# NANO103AE_v1 register map
File version: 1.0
Registers are 32-bit, read-write, reset 0x0 unless marked. A register's access mark holds for its fields unless they carry their own. Offsets are from the block's base; [hi:lo] are bit positions.

## WWDT — WWDT Register Map
Base 0x40004100
0x00 WWDT_RLDCNT wo — Window Watchdog Timer Reload Counter Register
  [31:0] RLDCNT — Window Watchdog Timer Reload Counter Register. Writing 0x00005AA5 to this register will reload the Window Watchdog Timer counter value to 0x3F. Note:This registercan only be written when WWDT counter value between 0 and WINCMP, otherwise WWDT will generate RESET signal.
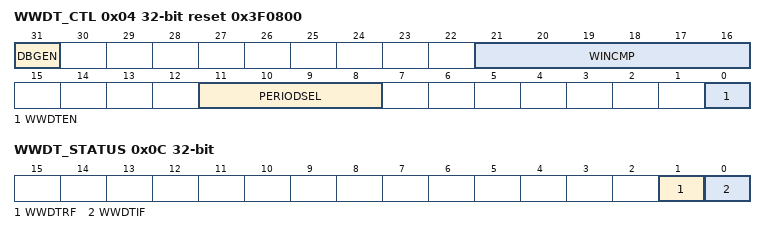
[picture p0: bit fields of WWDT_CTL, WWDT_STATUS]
0x04 WWDT_CTL reset 0x3F0800 — Window Watchdog Timer Control Register
  [31] DBGEN — WWDT Debug EnableBit
    0=WWDT stopped count if system is in Debug mode; 1=WWDT still counted even system is in Debug mode
  [21:16] WINCMP — WWDT Window Compare Bits. Set this register to adjust the valid reload window. Note:WWDT_RLDCNTregistercan only be written when WWDT counter value between 0 and WINCMP, otherwise WWDT will generate RESET signal.
  [11:8] PERIODSEL — WWDT Pre-scale Period Select. These three bits select the pre-scale for the WWDT counter period. Please refer toTable 6.121WWDT Prescaler Value Selection.
  [0] WWDTEN — Window Watchdog EnableBit. Set this bit to enable Window Watchdog timer.
    0=Window Watchdog timer function Disabled; 1=Window Watchdog timer function Enabled
0x08 WWDT_INTEN — Window Watchdog Timer Interrupt Enable Register
  [0] WWDTIEN — WWDT Interrupt Enable Bit. Setting this bit will enable the Window Watchdog timer interrupt function.
    0=Watchdog timer interrupt function Disabled; 1=Watchdog timer interrupt function Enabled
0x0C WWDT_STATUS — Window Watchdog Timer Status Register
  [1] WWDTRF — WWDT Reset Flag. When the WWDT counter down counts to 0 or writes WWDT_RLDCNT during WWDT counter larger than WINCMP, chip will be reset and this bit is set to 1. This bit can be cleared by writing '1' to it.
  [0] WWDTIF — WWDT Compare Match Interrupt Flag. When WWCMP matches the WWDT counter, this bit is set to 1. This bit can be cleared by writing '1' to it.
0x10 WWDT_CNT ro reset 0x3F — Window Watchdog Timer Counter Value Register
  [5:0] CNTDAT — WWDT Counter Value. This register reflects the current counter value of window watchdog.

## ACMP0 — ACMP0 Register Map
Base 0x401D0000
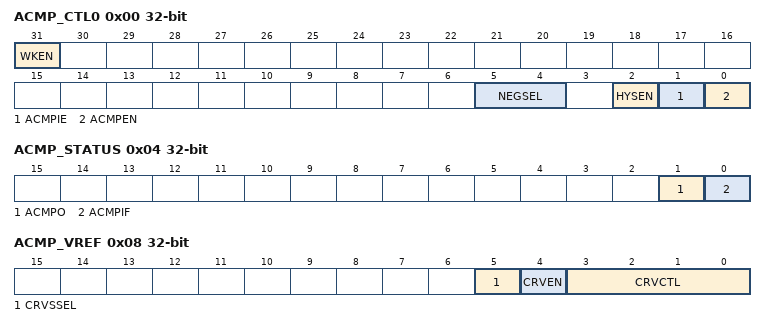
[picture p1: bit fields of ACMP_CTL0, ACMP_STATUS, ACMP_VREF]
0x00 ACMP_CTL0 — Analog Comparator 0 Control Register
  [31] WKEN — Power-down Wake-up Enable Bit
    0=Wake-up function Disabled; 1=Wake-up function Enabled
  [5:4] NEGSEL — Comparator Negative Input Selection
    0=ACMP0_N pin; 1=Internal comparator reference voltage (CRV); 2=Internal reference voltage (Int_VREF); 3=AVSS pin
  [2] HYSEN — Comparator Hysteresis Enable Bit
    0=Comparator 0 hysteresis Disabled; 1=Comparator 0 hysteresis Enabled
  [1] ACMPIE — Comparator Interrupt Enable Bit
    0=Comparator 0 interrupt Disabled; 1=Comparator 0 interrupt Enabled. If WKEN (ACMP_CTL0[31]) is set to 1, the wake-up interrupt function will be enabled as well
  [0] ACMPEN — Comparator Enable Bit
    0=Comparator 0 Disabled; 1=Comparator 0 Enabled
0x04 ACMP_STATUS — Analog Comparator Status Register
  [1] ACMPO — ComparatorOutput. Synchronized to the PCLK to allow reading by software. Cleared when the comparator 0 is disabled, i.e. ACMPEN (ACMP_CTL0[0]) is cleared to 0. Note: This bit is read only.
  [0] ACMPIF — ComparatorInterrupt Flag. This bit is set by hardware whenever the comparator 0 output changes state. This will generate an interrupt if ACMPIE (ACMP_CTL0[1]) is set to 1. Note: Write "1" to clear this bit to 0.
0x08 ACMP_VREF — Analog Comparator Reference Voltage Control Register
  [5] CRVSSEL — CRV Source Voltage Selection
    0=VDDA is selected as CRV source voltage; 1=The reference voltage defined by SYS_VREFCTL register is selected as CRV source voltage
  [4] CRVEN — CRV Enable Bit
    0=CRV Disabled; 1=CRV Enabled
  [3:0] CRVCTL — Comparator Reference Voltage Setting
